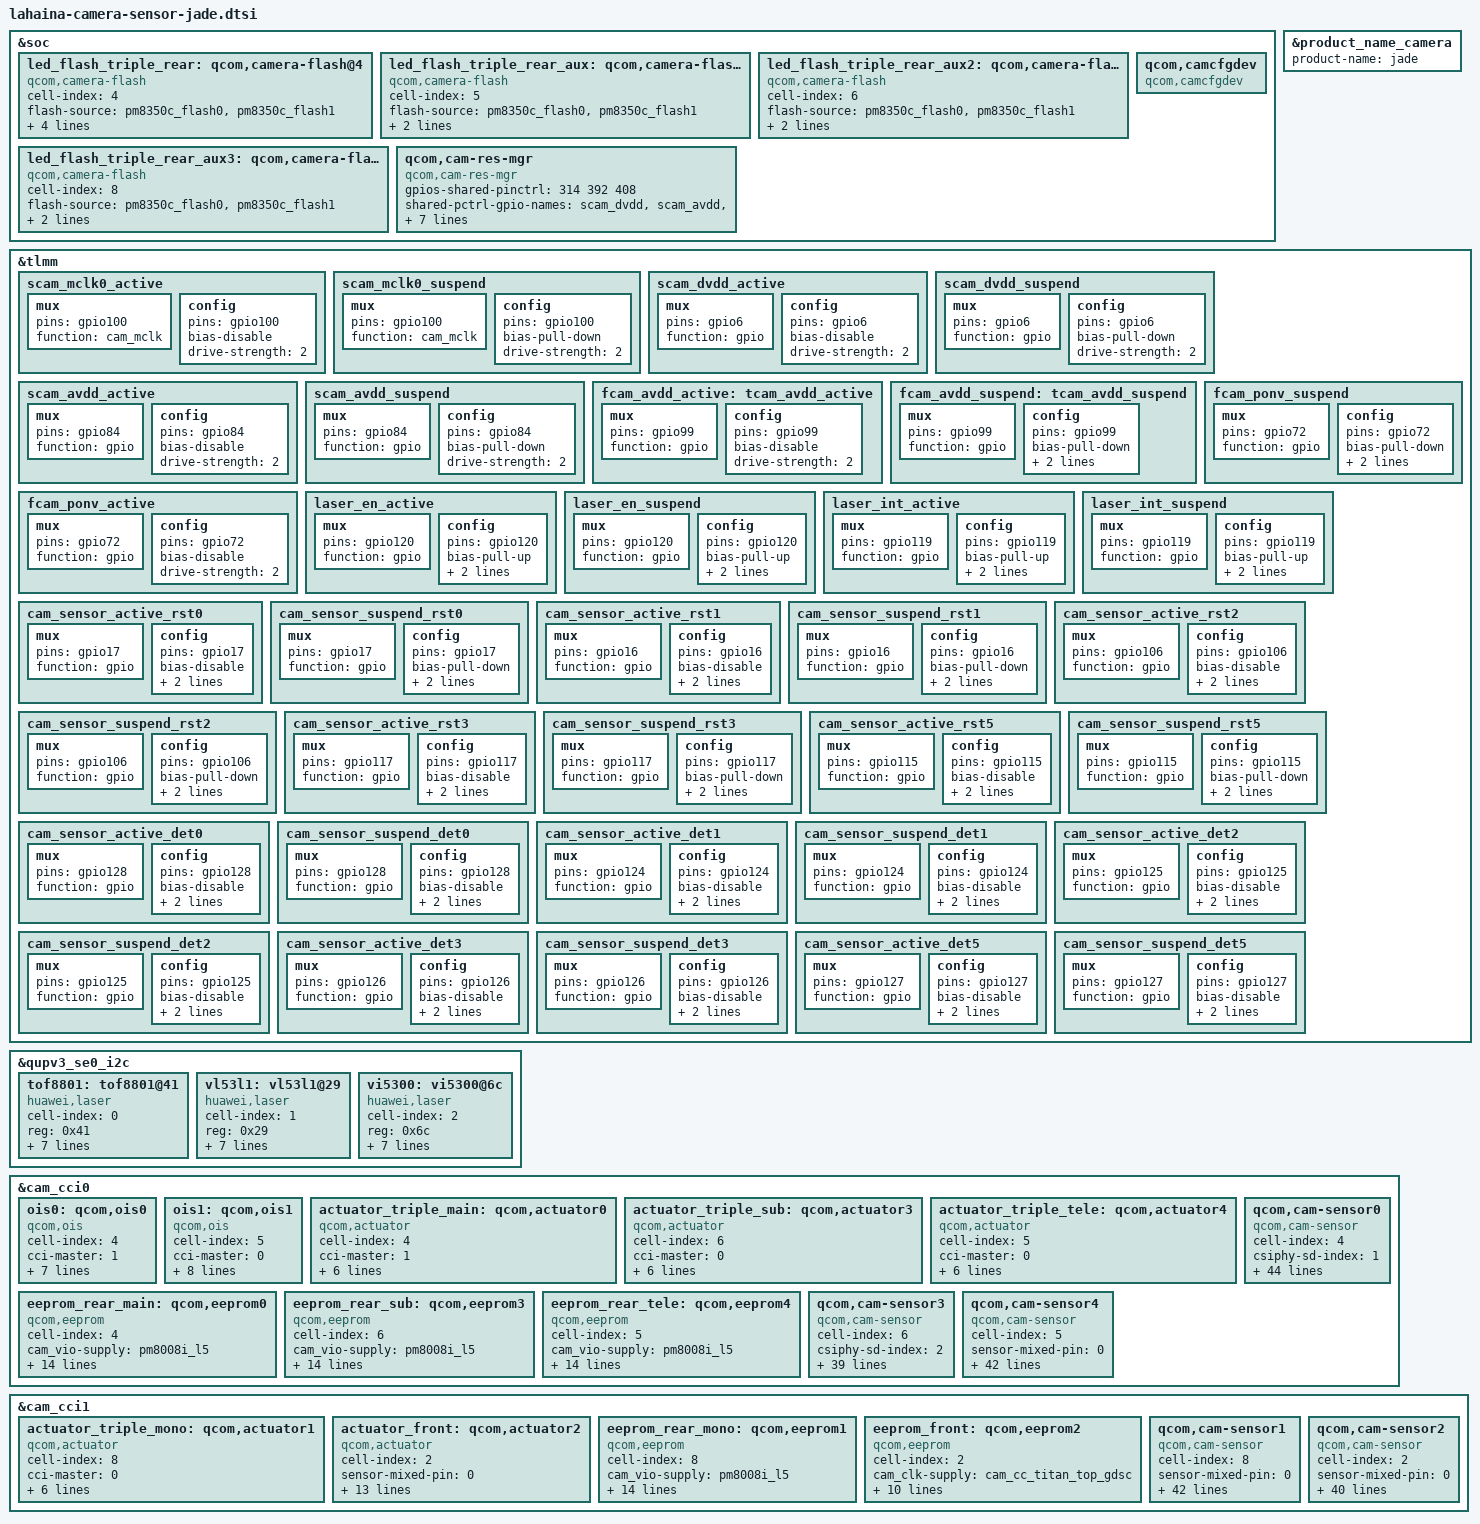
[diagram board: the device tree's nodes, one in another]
#include <dt-bindings/clock/qcom,camcc-lahaina.h>

&soc {
	led_flash_triple_rear: qcom,camera-flash@4 {
		cell-index = <4>;
		compatible = "qcom,camera-flash";
		flash-source = <&pm8350c_flash0 &pm8350c_flash1>;
		torch-source = <&pm8350c_torch0 &pm8350c_torch1>;
		switch-source = <&pm8350c_switch2>;
		torch-light-num = <0 1>;
		torch-light-name = "torch-light0", "torch-light1";
		status = "ok";
	};

	led_flash_triple_rear_aux: qcom,camera-flash@5 {
		cell-index = <5>;
		compatible = "qcom,camera-flash";
		flash-source = <&pm8350c_flash0 &pm8350c_flash1>;
		torch-source = <&pm8350c_torch0 &pm8350c_torch1>;
		switch-source = <&pm8350c_switch2>;
		status = "ok";
	};

	led_flash_triple_rear_aux2: qcom,camera-flash@6 {
		cell-index = <6>;
		compatible = "qcom,camera-flash";
		flash-source = <&pm8350c_flash0 &pm8350c_flash1>;
		torch-source = <&pm8350c_torch0 &pm8350c_torch1>;
		switch-source = <&pm8350c_switch2>;
		status = "ok";
	};

	led_flash_triple_rear_aux3: qcom,camera-flash@8 {
		cell-index = <8>;
		compatible = "qcom,camera-flash";
		flash-source = <&pm8350c_flash0 &pm8350c_flash1>;
		torch-source = <&pm8350c_torch0 &pm8350c_torch1>;
		switch-source = <&pm8350c_switch2>;
		status = "ok";
	};

	qcom,cam-res-mgr {
		compatible = "qcom,cam-res-mgr";
		status = "ok";
		gpios-shared-pinctrl = <314 392 408>;
		shared-pctrl-gpio-names = "scam_dvdd", "scam_avdd", "scam_mclk0";
		pinctrl-names = "scam_dvdd_active", "scam_dvdd_suspend", "scam_avdd_active",
			"scam_avdd_suspend", "scam_mclk0_active", "scam_mclk0_suspend";
		pinctrl-0 = <&scam_dvdd_active>;
		pinctrl-1 = <&scam_dvdd_suspend>;
		pinctrl-2 = <&scam_avdd_active>;
		pinctrl-3 = <&scam_avdd_suspend>;
		pinctrl-4 = <&scam_mclk0_active>;
		pinctrl-5 = <&scam_mclk0_suspend>;
	};

	qcom,camcfgdev {
		compatible = "qcom,camcfgdev";
		status = "ok";
	};
};

&product_name_camera {
    product-name = "jade";
};

&tlmm {
	scam_mclk0_active: scam_mclk0_active {
		/* MCLK0 */
		mux {
			pins = "gpio100";
			function = "cam_mclk";
		};

		config {
			pins = "gpio100";
			bias-disable; /* No PULL */
			drive-strength = <2>; /* 2 MA */
		};
	};

	scam_mclk0_suspend: scam_mclk0_suspend {
		/* MCLK0 */
		mux {
			pins = "gpio100";
			function = "cam_mclk";
		};

		config {
			pins = "gpio100";
			bias-pull-down; /* PULL DOWN */
			drive-strength = <2>; /* 2 MA */
		};
	};

	scam_dvdd_active: scam_dvdd_active {
		/* DVDD 0-for main */
		mux {
			pins = "gpio6";
			function = "gpio";
		};

		config {
			pins = "gpio6";
			bias-disable; /* No PULL */
			drive-strength = <2>; /* 2 MA */
		};
	};

	scam_dvdd_suspend: scam_dvdd_suspend {
		/* DVDD 0-for main */
		mux {
			pins = "gpio6";
			function = "gpio";
		};

		config {
			pins = "gpio6";
			bias-pull-down; /* PULL DOWN */
			drive-strength = <2>; /* 2 MA */
		};
	};

	scam_avdd_active: scam_avdd_active {
		/* AVDD 0-for main and front */
		mux {
			pins = "gpio84";
			function = "gpio";
		};

		config {
			pins = "gpio84";
			bias-disable; /* No PULL */
			drive-strength = <2>; /* 2 MA */
		};
	};

	scam_avdd_suspend: scam_avdd_suspend {
		/* AVDD 0-for main and front */
		mux {
			pins = "gpio84";
			function = "gpio";
		};

		config {
			pins = "gpio84";
			bias-pull-down; /* PULL DOWN */
			drive-strength = <2>; /* 2 MA */
		};
	};

	fcam_avdd_active: tcam_avdd_active {
		/* AVDD for font */
		mux {
			pins = "gpio99";
			function = "gpio";
		};

		config {
			pins = "gpio99";
			bias-disable; /* No PULL */
			drive-strength = <2>; /* 2 MA */
		};
	};

	fcam_avdd_suspend: tcam_avdd_suspend {
		/* AVDD for font */
		mux {
			pins = "gpio99";
			function = "gpio";
		};

		config {
			pins = "gpio99";
			bias-pull-down; /* PULL DOWN */
			drive-strength = <2>; /* 2 MA */
			output-low;
		};
	};

	fcam_ponv_active: fcam_ponv_active {
		/* fcam ponv */
		mux {
			pins = "gpio72";
			function = "gpio";
		};

		config {
			pins = "gpio72";
			bias-disable; /* No PULL */
			drive-strength = <2>; /* 2 MA */
		};
	};

	fcam_ponv_suspend: fcam_ponv_suspend {
		/* fcam ponv */
		mux {
			pins = "gpio72";
			function = "gpio";
		};

		config {
			pins = "gpio72";
			bias-pull-down; /* PULL DOWN */
			drive-strength = <2>; /* 2 MA */
			output-low;
		};
	};

	laser_en_active: laser_en_active {
		/* laser en pin */
		mux {
			pins = "gpio120";
			function = "gpio";
		};

		config {
			pins = "gpio120";
			bias-pull-up; /* PULL UP */
			drive-strength = <2>; /* 2 MA */
			input-enable;
		};
	};

	laser_en_suspend: laser_en_suspend {
		/* laser en pin */
		mux {
			pins = "gpio120";
			function = "gpio";
		};

		config {
			pins = "gpio120";
			bias-pull-up; /* PULL UP */
			drive-strength = <2>; /* 2 MA */
			input-enable;
		};
	};

	laser_int_active: laser_int_active {
		/* laser int pin */
		mux {
			pins = "gpio119";
			function = "gpio";
		};

		config {
			pins = "gpio119";
			bias-pull-up; /* PULL UP */
			drive-strength = <2>; /* 2 MA */
			input-enable;
		};
	};

	laser_int_suspend: laser_int_suspend {
		/* laser int pin */
		mux {
			pins = "gpio119";
			function = "gpio";
		};

		config {
			pins = "gpio119";
			bias-pull-up; /* PULL UP */
			drive-strength = <2>; /* 2 MA */
			input-enable;
		};
	};

	cam_sensor_active_rst0: cam_sensor_active_rst0 {
		/* RESET 0 */
		mux {
			pins = "gpio17";
			function = "gpio";
		};

		config {
			pins = "gpio17";
			bias-disable; /* No PULL */
			drive-strength = <2>; /* 2 MA */
			input-enable;
		};
	};

	cam_sensor_suspend_rst0: cam_sensor_suspend_rst0 {
		/* RESET 0 */
		mux {
			pins = "gpio17";
			function = "gpio";
		};

		config {
			pins = "gpio17";
			bias-pull-down; /* PULL DOWN */
			drive-strength = <2>; /* 2 MA */
			output-low;
		};
	};

	cam_sensor_active_rst1: cam_sensor_active_rst1 {
		/* RESET 1 */
		mux {
			pins = "gpio16";
			function = "gpio";
		};

		config {
			pins = "gpio16";
			bias-disable; /* No PULL */
			drive-strength = <2>; /* 2 MA */
			input-enable;
		};
	};

	cam_sensor_suspend_rst1: cam_sensor_suspend_rst1 {
		/* RESET 1 */
		mux {
			pins = "gpio16";
			function = "gpio";
		};

		config {
			pins = "gpio16";
			bias-pull-down; /* PULL DOWN */
			drive-strength = <2>; /* 2 MA */
			output-low;
		};
	};

	cam_sensor_active_rst2: cam_sensor_active_rst2 {
		/* RESET 2 */
		mux {
			pins = "gpio106";
			function = "gpio";
		};

		config {
			pins = "gpio106";
			bias-disable; /* No PULL */
			drive-strength = <2>; /* 2 MA */
			input-enable;
		};
	};

	cam_sensor_suspend_rst2: cam_sensor_suspend_rst2 {
		/* RESET 2 */
		mux {
			pins = "gpio106";
			function = "gpio";
		};

		config {
			pins = "gpio106";
			bias-pull-down; /* PULL DOWN */
			drive-strength = <2>; /* 2 MA */
			output-low;
		};
	};

	cam_sensor_active_rst3: cam_sensor_active_rst3 {
		/* RESET 3 */
		mux {
			pins = "gpio117";
			function = "gpio";
		};

		config {
			pins = "gpio117";
			bias-disable; /* No PULL */
			drive-strength = <2>; /* 2 MA */
			input-enable;
		};
	};

	cam_sensor_suspend_rst3: cam_sensor_suspend_rst3 {
		/* RESET 3 */
		mux {
			pins = "gpio117";
			function = "gpio";
		};

		config {
			pins = "gpio117";
			bias-pull-down; /* PULL DOWN */
			drive-strength = <2>; /* 2 MA */
			output-low;
		};
	};

	cam_sensor_active_rst5: cam_sensor_active_rst5 {
		/* RESET 5 */
		mux {
			pins = "gpio115";
			function = "gpio";
		};

		config {
			pins = "gpio115";
			bias-disable; /* No PULL */
			drive-strength = <2>; /* 2 MA */
			input-enable;
		};
	};

	cam_sensor_suspend_rst5: cam_sensor_suspend_rst5 {
		/* RESET 5 */
		mux {
			pins = "gpio115";
			function = "gpio";
		};

		config {
			pins = "gpio115";
			bias-pull-down; /* PULL DOWN */
			drive-strength = <2>; /* 2 MA */
			output-low;
		};
	};

	cam_sensor_active_det0: cam_sensor_active_det0 {
		/* BTB_DET 0 */
		mux {
			pins = "gpio128";
			function = "gpio";
		};

		config {
			pins = "gpio128";
			bias-disable; /* No PULL */
			drive-strength = <2>; /* 2 MA */
			input-enable;
		};
	};

	cam_sensor_suspend_det0: cam_sensor_suspend_det0 {
		/* BTB_DET 0 */
		mux {
			pins = "gpio128";
			function = "gpio";
		};

		config {
			pins = "gpio128";
			bias-disable; /* No PULL */
			drive-strength = <2>; /* 2 MA */
			input-enable;
		};
	};

	cam_sensor_active_det1: cam_sensor_active_det1 {
		/* BTB_DET 1 */
		mux {
			pins = "gpio124";
			function = "gpio";
		};

		config {
			pins = "gpio124";
			bias-disable; /* No PULL */
			drive-strength = <2>; /* 2 MA */
			input-enable;
		};
	};

	cam_sensor_suspend_det1: cam_sensor_suspend_det1 {
		/* BTB_DET 1 */
		mux {
			pins = "gpio124";
			function = "gpio";
		};

		config {
			pins = "gpio124";
			bias-disable; /* No PULL */
			drive-strength = <2>; /* 2 MA */
			input-enable;
		};
	};

	cam_sensor_active_det2: cam_sensor_active_det2 {
		/* BTB_DET 2 */
		mux {
			pins = "gpio125";
			function = "gpio";
		};

		config {
			pins = "gpio125";
			bias-disable; /* No PULL */
			drive-strength = <2>; /* 2 MA */
			input-enable;
		};
	};

	cam_sensor_suspend_det2: cam_sensor_suspend_det2 {
		/* BTB_DET 2 */
		mux {
			pins = "gpio125";
			function = "gpio";
		};

		config {
			pins = "gpio125";
			bias-disable; /* No PULL */
			drive-strength = <2>; /* 2 MA */
			input-enable;
		};
	};

	cam_sensor_active_det3: cam_sensor_active_det3 {
		/* BTB_DET 3 */
		mux {
			pins = "gpio126";
			function = "gpio";
		};

		config {
			pins = "gpio126";
			bias-disable; /* No PULL */
			drive-strength = <2>; /* 2 MA */
			input-enable;
		};
	};

	cam_sensor_suspend_det3: cam_sensor_suspend_det3 {
		/* BTB_DET 3 */
		mux {
			pins = "gpio126";
			function = "gpio";
		};

		config {
			pins = "gpio126";
			bias-disable; /* No PULL */
			drive-strength = <2>; /* 2 MA */
			input-enable;
		};
	};

	cam_sensor_active_det5: cam_sensor_active_det5 {
		/* BTB_DET 5 */
		mux {
			pins = "gpio127";
			function = "gpio";
		};

		config {
			pins = "gpio127";
			bias-disable; /* No PULL */
			drive-strength = <2>; /* 2 MA */
			input-enable;
		};
	};

	cam_sensor_suspend_det5: cam_sensor_suspend_det5 {
		/* BTB_DET 5 */
		mux {
			pins = "gpio127";
			function = "gpio";
		};

		config {
			pins = "gpio127";
			bias-disable; /* No PULL */
			drive-strength = <2>; /* 2 MA */
			input-enable;
		};
	};
};

/* laser */
&qupv3_se0_i2c {
	status = "ok";

	tof8801: tof8801@41 {
		cell-index = <0>;
		compatible = "huawei,laser";
		reg = <0x41>;
		vdd_ana-supply = <&pm8350_l7>;
		gpios = <&tlmm 120 0>,
			<&tlmm 119 0>;
		pinctrl-names = "laser_int_active", "laser_en_active";
		pinctrl-0 = <&laser_int_active>;
		pinctrl-1 = <&laser_en_active>;
		gpio-req-tbl-num = <0>;
		gpio-req-tbl-flags = <0>;
		gpio-req-tbl-label = "CAM_VAF0";
		status = "ok";
	};

	vl53l1: vl53l1@29 {
		cell-index = <1>;
		compatible = "huawei,laser";
		reg = <0x29>;
		vdd_ana-supply = <&pm8350_l7>;
		gpios = <&tlmm 120 0>,
			<&tlmm 119 0>;
		pinctrl-names = "laser_int_active", "laser_en_active";
		pinctrl-0 = <&laser_int_active>;
		pinctrl-1 = <&laser_en_active>;
		gpio-req-tbl-num = <0>;
		gpio-req-tbl-flags = <0>;
		gpio-req-tbl-label = "CAM_VAF0";
		status = "ok";
	};

	vi5300: vi5300@6c {
		cell-index = <2>;
		compatible = "huawei,laser";
		reg = <0x6c>;
		vdd_ana-supply = <&pm8350_l7>;
		gpios = <&tlmm 120 0>,
			<&tlmm 119 0>;
		pinctrl-names = "laser_int_active", "laser_en_active";
		pinctrl-0 = <&laser_int_active>;
		pinctrl-1 = <&laser_en_active>;
		gpio-req-tbl-num = <0>;
		gpio-req-tbl-flags = <0>;
		gpio-req-tbl-label = "CAM_VAF0";
		status = "ok";
	};
};

&cam_cci0 {
	ois0: qcom,ois0 {
		cell-index = <4>;
		compatible = "qcom,ois";
		cci-master = <1>;
		cam_vio-supply = <&pm8008i_l5>;
		cam_vdig-supply = <&pm8008i_l4>;
		regulator-names = "cam_vio", "cam_vdig";
		rgltr-cntrl-support;
		rgltr-min-voltage = <1800000 3140000>;
		rgltr-max-voltage = <1900000 3200000>;
		rgltr-load-current = <74000 103000>;
	};

	ois1: qcom,ois1 {
		cell-index = <5>;
		compatible = "qcom,ois";
		cci-master = <0>;
		cam_vio-supply = <&pm8008i_l5>;
		cam_vdig-supply = <&pm8008i_l4>;
		cam_vaf-supply = <&pm8008i_l3>;
		regulator-names = "cam_vio", "cam_vdig", "cam_vaf";
		rgltr-cntrl-support;
		rgltr-min-voltage = <1800000 3140000 3200000>;
		rgltr-max-voltage = <1900000 3200000 3200000>;
		rgltr-load-current = <74000 103000 103000>;
	};

	actuator_triple_main: qcom,actuator0 {
		cell-index = <4>;
		compatible = "qcom,actuator";
		cci-master = <1>;
		cam_vaf-supply = <&pm8008i_l3>;
		regulator-names = "cam_vaf";
		rgltr-cntrl-support;
		rgltr-min-voltage = <3200000>;
		rgltr-max-voltage = <3200000>;
		rgltr-load-current = <103000>;
	};

	actuator_triple_sub: qcom,actuator3 {
		cell-index = <6>;
		compatible = "qcom,actuator";
		cci-master = <0>;
		cam_vaf-supply = <&pm8008i_l3>;
		regulator-names = "cam_vaf";
		rgltr-cntrl-support;
		rgltr-min-voltage = <3200000>;
		rgltr-max-voltage = <3200000>;
		rgltr-load-current = <103000>;
	};

	actuator_triple_tele: qcom,actuator4 {
		cell-index = <5>;
		compatible = "qcom,actuator";
		cci-master = <0>;
		cam_vaf-supply = <&pm8008i_l3>;
		regulator-names = "cam_vaf";
		rgltr-cntrl-support;
		rgltr-min-voltage = <3200000>;
		rgltr-max-voltage = <3200000>;
		rgltr-load-current = <103000>;
	};

	eeprom_rear_main: qcom,eeprom0 {
		cell-index = <4>;
		compatible = "qcom,eeprom";
		cam_vio-supply = <&pm8008i_l5>;
		cam_vdig-supply = <&pm8008i_l4>;
		cam_vaf-supply = <&pm8008i_l3>;
		cam_clk-supply = <&cam_cc_titan_top_gdsc>;
		regulator-names = "cam_vio", "cam_vdig", "cam_vaf", "cam_clk";
		rgltr-cntrl-support;
		rgltr-min-voltage = <1800000 3140000 3200000 0>;
		rgltr-max-voltage = <1900000 3200000 3200000 0>;
		rgltr-load-current = <74000 103000 103000 0>;
		gpio-no-mux = <0>;
		cci-master = <1>;
		status = "ok";
		clocks = <&clock_camcc CAM_CC_MCLK1_CLK>;
		clock-names = "cam_clk";
		clock-cntl-level = "nominal";
		clock-rates = <19200000>;
	};

	eeprom_rear_sub: qcom,eeprom3 {
		cell-index = <6>;
		compatible = "qcom,eeprom";
		cam_vio-supply = <&pm8008i_l5>;
		cam_vdig-supply = <&pm8008i_l4>;
		cam_vaf-supply = <&pm8008i_l3>;
		cam_clk-supply = <&cam_cc_titan_top_gdsc>;
		regulator-names = "cam_vio", "cam_vdig", "cam_vaf", "cam_clk";
		rgltr-cntrl-support;
		rgltr-min-voltage = <1800000 3140000 3200000 0>;
		rgltr-max-voltage = <1900000 3200000 3200000 0>;
		rgltr-load-current = <74000 103000 103000 0>;
		gpio-no-mux = <0>;
		cci-master = <0>;
		status = "ok";
		clocks = <&clock_camcc CAM_CC_MCLK0_CLK>;
		clock-names = "cam_clk";
		clock-cntl-level = "nominal";
		clock-rates = <19200000>;
	};

	eeprom_rear_tele: qcom,eeprom4 {
		cell-index = <5>;
		compatible = "qcom,eeprom";
		cam_vio-supply = <&pm8008i_l5>;
		cam_vdig-supply = <&pm8008i_l4>;
		cam_vaf-supply = <&pm8008i_l3>;
		cam_clk-supply = <&cam_cc_titan_top_gdsc>;
		regulator-names = "cam_vio", "cam_vdig", "cam_vaf", "cam_clk";
		rgltr-cntrl-support;
		rgltr-min-voltage = <1800000 3140000 3200000 0>;
		rgltr-max-voltage = <1900000 3200000 3200000 0>;
		rgltr-load-current = <74000 103000 103000 0>;
		gpio-no-mux = <0>;
		cci-master = <0>;
		status = "ok";
		clocks = <&clock_camcc CAM_CC_MCLK0_CLK>;
		clock-names = "cam_clk";
		clock-cntl-level = "nominal";
		clock-rates = <19200000>;
	};

	/* back main sensor */
	qcom,cam-sensor0 {
		cell-index = <4>;
		compatible = "qcom,cam-sensor";
		csiphy-sd-index = <1>;
		sensor-position-roll = <90>;
		sensor-position-pitch = <0>;
		sensor-position-yaw = <180>;
		eeprom-src = <&eeprom_rear_main>;
		actuator-src = <&actuator_triple_main>;
		led-flash-src = <&led_flash_triple_rear>;
		ois-src  = <&ois0>;
		cam_vio-supply = <&pm8008i_l5>;
		cam_vana-supply = <&pm8008i_l7>;
		cam_vdig-supply = <&pm8008i_l4>;
		cam_vaf-supply = <&pm8008i_l3>;
		cam_clk-supply = <&cam_cc_titan_top_gdsc>;
		regulator-names = "cam_vio", "cam_vana", "cam_vdig", "cam_vaf", "cam_clk";
		rgltr-cntrl-support;
		rgltr-min-voltage = <1800000 2850000 3140000 3200000 0>;
		rgltr-max-voltage = <1900000 2950000 3200000 3200000 0>;
		rgltr-load-current = <74000 103000 103000 103000 0>;
		gpio-no-mux = <0>;
		pinctrl-names = "cam_default", "cam_suspend";
		pinctrl-0 = <&cam_sensor_mclk1_active
				&cam_sensor_active_rst1
				&cam_sensor_active_det1>;
		pinctrl-1 = <&cam_sensor_mclk1_suspend
				&cam_sensor_suspend_rst1
				&cam_sensor_suspend_det1>;
		gpios = <&tlmm 101 0>,
			<&tlmm 16 0>,
			<&tlmm 84 0>,
			<&tlmm 6 0>,
			<&tlmm 124 0>;
		gpio-reset = <1>;
		gpio-custom1 = <2>;
		gpio-custom2 = <3>;
		gpio-btb-det = <4>;
		gpio-req-tbl-num = <0 1 2 3 4>;
		gpio-req-tbl-flags = <1 0 0 0 0>;
		gpio-req-tbl-label = "CAMIF_MCLK0",
					"CAM_RESET0",
					"CAM_CUSTOM1",
					"CAM_CUSTOM2",
					"CAM_BTB_DET1";
		cci-master = <1>;
		status = "ok";
		clocks = <&clock_camcc CAM_CC_MCLK1_CLK>;
		clock-names = "cam_clk";
		clock-cntl-level = "nominal";
		clock-rates = <19200000>;
		ic_position = <0>; /* CAMERA_POSITION_REAR */
		btb_check = <1>; /* need btb check */
	};

	/* back wide sensor */
	qcom,cam-sensor3 {
		cell-index = <6>;
		compatible = "qcom,cam-sensor";
		csiphy-sd-index = <2>;
		sensor-position-roll = <90>;
		sensor-position-pitch = <0>;
		sensor-position-yaw = <180>;
		actuator-src = <&actuator_triple_sub>;
		eeprom-src = <&eeprom_rear_sub>;
		led-flash-src = <&led_flash_triple_rear_aux2>;
		cam_vana-supply = <&pm8008i_l6>;
		cam_vio-supply = <&pm8008i_l5>;
		cam_vdig-supply = <&pm8008i_l2>;
		cam_v_custom1-supply = <&pm8008i_l4>;
		cam_vaf-supply = <&pm8008i_l3>;
		cam_clk-supply = <&cam_cc_titan_top_gdsc>;
		regulator-names = "cam_vana", "cam_vio", "cam_vdig", "cam_v_custom1", "cam_vaf", "cam_clk";
		rgltr-cntrl-support;
		rgltr-min-voltage = <2850000 1800000 1216000 3140000 3200000 0>;
		rgltr-max-voltage = <2950000 1900000 1220000 3200000 3200000 0>;
		rgltr-load-current = <200000 74000 140000 103000 103000 0>;
		gpio-no-mux = <0>;
		pinctrl-names = "cam_default", "cam_suspend";
		pinctrl-0 = <&cam_sensor_active_rst2
				&cam_sensor_active_det2>;
		pinctrl-1 = <&cam_sensor_suspend_rst2
				&cam_sensor_suspend_det2>;
		gpios = <&tlmm 100 0>,
			<&tlmm 106 0>,
			<&tlmm 125 0>;
		gpio-reset = <1>;
		gpio-btb-det = <2>;
		gpio-req-tbl-num = <0 1 2>;
		gpio-req-tbl-flags = <1 0 0>;
		gpio-req-tbl-label = "CAMIF_MCLK4",
					"CAM_RESET4",
					"CAM_BTB_DET2";
		cci-master = <0>;
		status = "ok";
		clocks = <&clock_camcc CAM_CC_MCLK0_CLK>;
		clock-names = "cam_clk";
		clock-cntl-level = "nominal";
		clock-rates = <19200000>;
		ic_position = <2>; /* CAMERA_POSITION_REAR_SECOND */
		btb_check = <1>; /* need btb check */
	};

	/* back tele sensor */
	qcom,cam-sensor4 {
		cell-index = <5>;
		compatible = "qcom,cam-sensor";
		sensor-mixed-pin = <0>;
		csiphy-sd-index = <0>;
		sensor-position-roll = <90>;
		sensor-position-pitch = <0>;
		sensor-position-yaw = <180>;
		actuator-src = <&actuator_triple_tele>;
		eeprom-src = <&eeprom_rear_tele>;
		ois-src  = <&ois1>;
		led-flash-src = <&led_flash_triple_rear_aux>;
		cam_vio-supply = <&pm8008i_l5>;
		cam_vdig-supply = <&pm8008i_l4>;
		cam_vaf-supply = <&pm8008i_l3>;
		cam_clk-supply = <&cam_cc_titan_top_gdsc>;
		regulator-names = "cam_vio", "cam_vdig", "cam_vaf", "cam_clk";
		rgltr-cntrl-support;
		rgltr-min-voltage = <1800000 3140000 3200000 0>;
		rgltr-max-voltage = <1900000 3200000 3200000 0>;
		rgltr-load-current = <74000 103000 103000 0>;
		gpio-no-mux = <0>;
		pinctrl-names = "cam_default", "cam_suspend";
		pinctrl-0 = <&fcam_avdd_active
				&cam_sensor_active_rst3
				&cam_sensor_active_det3>;
		pinctrl-1 = <&fcam_avdd_suspend
				&cam_sensor_suspend_rst3
				&cam_sensor_suspend_det3>;
		gpios = <&tlmm 100 0>,
			<&tlmm 117 0>,
			<&tlmm 6 0>,
			<&tlmm 99 0>,
			<&tlmm 126 0>;
		gpio-reset = <1>;
		gpio-custom1 = <2>; /* DVDD 1.17V */
		gpio-mixed1 = <3>; /* AVDD 2.85V */
		gpio-btb-det = <4>;
		gpio-req-tbl-num = <0 1 2 3 4>;
		gpio-req-tbl-flags = <1 0 0 0 0>;
		gpio-req-tbl-label = "CAMIF_MCLK5",
					"CAM_RESET5",
					"CAM_TELE_CUSTOM1",
					"CAM_TELE_MIXED",
					"CAM_BTB_DET3";
		cci-master = <0>;
		status = "ok";
		clocks = <&clock_camcc CAM_CC_MCLK0_CLK>;
		clock-names = "cam_clk";
		clock-cntl-level = "nominal";
		clock-rates = <19200000>;
		ic_position = <4>; /* CAMERA_POSITION_REAR_THIRD */
		btb_check = <1>; /* need btb check */
	};
};

&cam_cci1 {
	actuator_triple_mono: qcom,actuator1 {
		cell-index = <8>;
		compatible = "qcom,actuator";
		cci-master = <0>;
		cam_vaf-supply = <&pm8008i_l3>;
		regulator-names = "cam_vaf";
		rgltr-cntrl-support;
		rgltr-min-voltage = <3200000>;
		rgltr-max-voltage = <3200000>;
		rgltr-load-current = <103000>;
	};

	actuator_front: qcom,actuator2 {
		cell-index = <2>;
		compatible = "qcom,actuator";
		sensor-mixed-pin = <0>;
		cam_clk-supply = <&cam_cc_titan_top_gdsc>;
		regulator-names = "cam_clk";
		rgltr-cntrl-support;
		rgltr-min-voltage = <0>;
		rgltr-max-voltage = <0>;
		rgltr-load-current = <0>;
		gpio-no-mux = <0>;
		gpios = <&tlmm 49 0>;
		gpio-mixed1 = <0>;
		gpio-req-tbl-num = <0>;
		gpio-req-tbl-flags = <0>;
		gpio-req-tbl-label = "CAM_VAF2";
		cci-master = <1>;
		status = "ok";
	};

	eeprom_rear_mono: qcom,eeprom1 {
		cell-index = <8>;
		compatible = "qcom,eeprom";
		cam_vio-supply = <&pm8008i_l5>;
		cam_vdig-supply = <&pm8008i_l4>;
		cam_vaf-supply = <&pm8008i_l3>;
		cam_clk-supply = <&cam_cc_titan_top_gdsc>;
		regulator-names = "cam_vio", "cam_vdig", "cam_vaf", "cam_clk";
		rgltr-cntrl-support;
		rgltr-min-voltage = <1800000 3140000 3200000 0>;
		rgltr-max-voltage = <1900000 3200000 3200000 0>;
		rgltr-load-current = <74000 103000 103000 0>;
		gpio-no-mux = <0>;
		cci-master = <0>;
		status = "ok";
		clocks = <&clock_camcc CAM_CC_MCLK2_CLK>;
		clock-names = "cam_clk";
		clock-cntl-level = "nominal";
		clock-rates = <19200000>;
	};

	eeprom_front: qcom,eeprom2 {
		cell-index = <2>;
		compatible = "qcom,eeprom";
		cam_clk-supply = <&cam_cc_titan_top_gdsc>;
		regulator-names = "cam_clk";
		rgltr-cntrl-support;
		rgltr-min-voltage = <0>;
		rgltr-max-voltage = <0>;
		rgltr-load-current = <0>;
		gpio-no-mux = <0>;
		cci-master = <1>;
		status = "ok";
		clocks = <&clock_camcc CAM_CC_MCLK3_CLK>;
		clock-names = "cam_clk";
		clock-cntl-level = "nominal";
		clock-rates = <19200000>;
	};

	/* back mono sensor */
	qcom,cam-sensor1 {
		cell-index = <8>;
		compatible = "qcom,cam-sensor";
		sensor-mixed-pin = <0>;
		csiphy-sd-index = <3>;
		sensor-position-roll = <90>;
		sensor-position-pitch = <0>;
		sensor-position-yaw = <180>;
		actuator-src = <&actuator_triple_mono>;
		eeprom-src = <&eeprom_rear_mono>;
		led-flash-src = <&led_flash_triple_rear_aux3>;
		cam_vio-supply = <&pm8008i_l5>;
		cam_vana-supply = <&pm8008i_l6>;
		cam_vdig-supply = <&pm8008i_l4>;
		cam_vaf-supply = <&pm8008i_l3>;
		cam_clk-supply = <&cam_cc_titan_top_gdsc>;
		regulator-names = "cam_vio", "cam_vana", "cam_vdig", "cam_vaf", "cam_clk";
		rgltr-cntrl-support;
		rgltr-min-voltage = <1800000 2850000 3140000 3200000 0>;
		rgltr-max-voltage = <1900000 2900000 3200000 3200000 0>;
		rgltr-load-current = <74000 52000 103000 103000 0>;
		gpio-no-mux = <0>;
		pinctrl-names = "cam_default", "cam_suspend";
		pinctrl-0 = <&cam_sensor_mclk2_active
			&cam_sensor_active_rst5
			&cam_sensor_active_det5>;
		pinctrl-1 = <&cam_sensor_mclk2_suspend
			&cam_sensor_suspend_rst5
			&cam_sensor_suspend_det5>;
		gpios = <&tlmm 102 0>,
			<&tlmm 115 0>,
			<&tlmm 6 0>,
			<&tlmm 127 0>;
		gpio-reset = <1>;
		gpio-mixed1 = <2>; /* DVDD 1.17V */
		gpio-btb-det = <3>;
		gpio-req-tbl-num = <0 1 2 3>;
		gpio-req-tbl-flags = <1 0 0 0>;
		gpio-req-tbl-label = "CAMIF_MCLK1",
					"CAM_RESET1",
					"CAM_MONO_CUSTOM1",
					"CAM_BTB_DET5";
		cci-master = <0>;
		status = "ok";
		clocks = <&clock_camcc CAM_CC_MCLK2_CLK>;
		clock-names = "cam_clk";
		clock-cntl-level = "nominal";
		clock-rates = <19200000>;
		ic_position = <6>; /* CAMERA_POSITION_REAR_FORTH */
		btb_check = <1>; /* need btb check */
	};

	/* front main sensor */
	qcom,cam-sensor2 {
		cell-index = <2>;
		compatible = "qcom,cam-sensor";
		sensor-mixed-pin = <0>;
		csiphy-sd-index = <5>;
		sensor-position-roll = <270>;
		sensor-position-pitch = <0>;
		sensor-position-yaw = <0>;
		actuator-src = <&actuator_front>;
		eeprom-src = <&eeprom_front>;
		cam_vdig-supply = <&pm8008i_l1>;
		cam_clk-supply = <&cam_cc_titan_top_gdsc>;
		regulator-names = "cam_vdig", "cam_clk";
		rgltr-cntrl-support;
		rgltr-min-voltage = <1100000 0>;
		rgltr-max-voltage = <1104000 0>;
		rgltr-load-current = <150000 0>;
		gpio-no-mux = <0>;
		pinctrl-names = "cam_default", "cam_suspend";
		pinctrl-0 = <&cam_sensor_mclk3_active
				&fcam_avdd_active
				&fcam_ponv_active
				&cam_sensor_active_rst0
				&cam_sensor_active_det0>;
		pinctrl-1 = <&cam_sensor_mclk3_suspend
				&fcam_avdd_suspend
				&fcam_ponv_suspend
				&cam_sensor_suspend_rst0
				&cam_sensor_suspend_det0>;
		gpios = <&tlmm 103 0>,
			<&tlmm 17 0>,
			<&tlmm 84 0>,
			<&tlmm 72 0>,
			<&tlmm 99 0>,
			<&tlmm 128 0>;
		gpio-reset = <1>;
		gpio-custom1 = <2>; /* AVDD 1.8V */
		gpio-custom2 = <3>; /* PONV */
		gpio-mixed1 = <4>; /* AVDD 2.85V */
		gpio-btb-det = <5>;
		gpio-req-tbl-num = <0 1 2 3 4 5>;
		gpio-req-tbl-flags = <1 0 0 0 0 0>;
		gpio-req-tbl-label = "CAMIF_MCLK2",
					"CAM_RESET2",
					"CAM_FONT_CUSTOM1",
					"CAM_FONT_CUSTOM2",
					"CAM_FONT_MIXED",
					"CAM_BTB_DET0";
		cci-master = <1>;
		status = "ok";
		clocks = <&clock_camcc CAM_CC_MCLK3_CLK>;
		clock-names = "cam_clk";
		clock-cntl-level = "nominal";
		clock-rates = <19200000>;
		ic_position = <1>; /* CAMERA_POSITION_FORE */
		btb_check = <1>; /* need btb check */
	};
};
